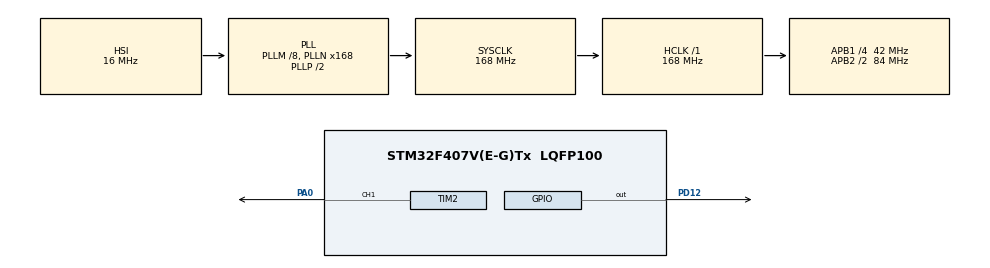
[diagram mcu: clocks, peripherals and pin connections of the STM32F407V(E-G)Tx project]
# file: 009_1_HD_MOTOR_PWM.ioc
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Mcu.Family=STM32F4
Mcu.Name=STM32F407V(E-G)Tx
Mcu.Package=LQFP100
NVIC.PriorityGroup=NVIC_PRIORITYGROUP_4
PA0-WKUP.Signal=S_TIM2_CH1_ETR
PD12.Signal=GPIO_Output
ProjectManager.HeapSize=0x200
ProjectManager.StackSize=0x400
ProjectManager.TargetToolchain=STM32CubeIDE
RCC.48MHZClocksFreq_Value=84000000
RCC.AHBFreq_Value=168000000
RCC.APB1CLKDivider=RCC_HCLK_DIV4
RCC.APB1Freq_Value=42000000
RCC.APB1TimFreq_Value=84000000
RCC.APB2CLKDivider=RCC_HCLK_DIV2
RCC.APB2Freq_Value=84000000
RCC.APB2TimFreq_Value=168000000
RCC.CortexFreq_Value=168000000
RCC.HCLKFreq_Value=168000000
RCC.HSE_VALUE=25000000
RCC.HSI_VALUE=16000000
RCC.LSE_VALUE=32768
RCC.PLLM=8
RCC.PLLN=168
RCC.SYSCLKFreq_VALUE=168000000
RCC.SYSCLKSource=RCC_SYSCLKSOURCE_PLLCLK
RCC.VCOOutputFreq_Value=336000000
SH.S_TIM2_CH1_ETR.0=TIM2_CH1,PWM Generation1 CH1
TIM2.Channel-PWM\ Generation1\ CH1=TIM_CHANNEL_1
TIM2.Period=124
TIM2.Prescaler=83
board=custom

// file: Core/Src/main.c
/* USER CODE BEGIN Header */
/**
  ******************************************************************************
  * @file           : main.c
  * @brief          : Main program body
  ******************************************************************************
  * @attention
  *
  * <h2><center>&copy; Copyright (c) 2020 STMicroelectronics.
  * All rights reserved.</center></h2>
  *
  * This software component is licensed by ST under BSD 3-Clause license,
  * the "License"; You may not use this file except in compliance with the
  * License. You may obtain a copy of the License at:
  *                        opensource.org/licenses/BSD-3-Clause
  *
  ******************************************************************************
  */
/* USER CODE END Header */

#include "main.h"

/* USER CODE BEGIN Includes */

int count;
int i;

/* USER CODE END Includes */

TIM_HandleTypeDef htim2;

void SystemClock_Config(void);
static void MX_GPIO_Init(void);
static void MX_TIM2_Init(void);

int main(void)
{

  /* MCU Configuration--------------------------------------------------------*/

  /* Reset of all peripherals, Initializes the Flash interface and the Systick. */
  HAL_Init();

  /* Configure the system clock */
  SystemClock_Config();

  /* Initialize all configured peripherals */
  MX_GPIO_Init();
  MX_TIM2_Init();
  /* USER CODE BEGIN 2 */
 HAL_TIM_PWM_Start(&htim2, TIM_CHANNEL_1);
  /* USER CODE END 2 */

  /* Infinite loop */
  /* USER CODE BEGIN WHILE */
  while (1)
  {
	  for(i = 0; i <= 125; i++)
	  {
		  __HAL_TIM_SET_COMPARE(&htim2, TIM_CHANNEL_1, i);
		  HAL_Delay(50);
		  count = i;

	  }
	  HAL_GPIO_WritePin(GPIOD, GPIO_PIN_12, GPIO_PIN_SET);
    /* USER CODE END WHILE */

  }
}

void SystemClock_Config(void)
{
  RCC_OscInitTypeDef RCC_OscInitStruct = {0};
  RCC_ClkInitTypeDef RCC_ClkInitStruct = {0};

  /** Configure the main internal regulator output voltage
  */
  __HAL_RCC_PWR_CLK_ENABLE();
  __HAL_PWR_VOLTAGESCALING_CONFIG(PWR_REGULATOR_VOLTAGE_SCALE1);
  /** Initializes the CPU, AHB and APB busses clocks
  */
  RCC_OscInitStruct.OscillatorType = RCC_OSCILLATORTYPE_HSI;
  RCC_OscInitStruct.HSIState = RCC_HSI_ON;
  RCC_OscInitStruct.HSICalibrationValue = RCC_HSICALIBRATION_DEFAULT;
  RCC_OscInitStruct.PLL.PLLState = RCC_PLL_ON;
  RCC_OscInitStruct.PLL.PLLSource = RCC_PLLSOURCE_HSI;
  RCC_OscInitStruct.PLL.PLLM = 8;
  RCC_OscInitStruct.PLL.PLLN = 168;
  RCC_OscInitStruct.PLL.PLLP = RCC_PLLP_DIV2;
  RCC_OscInitStruct.PLL.PLLQ = 4;
  if (HAL_RCC_OscConfig(&RCC_OscInitStruct) != HAL_OK)
  {
    Error_Handler();
  }
  /** Initializes the CPU, AHB and APB busses clocks
  */
  RCC_ClkInitStruct.ClockType = RCC_CLOCKTYPE_HCLK|RCC_CLOCKTYPE_SYSCLK
                              |RCC_CLOCKTYPE_PCLK1|RCC_CLOCKTYPE_PCLK2;
  RCC_ClkInitStruct.SYSCLKSource = RCC_SYSCLKSOURCE_PLLCLK;
  RCC_ClkInitStruct.AHBCLKDivider = RCC_SYSCLK_DIV1;
  RCC_ClkInitStruct.APB1CLKDivider = RCC_HCLK_DIV4;
  RCC_ClkInitStruct.APB2CLKDivider = RCC_HCLK_DIV2;

  if (HAL_RCC_ClockConfig(&RCC_ClkInitStruct, FLASH_LATENCY_5) != HAL_OK)
  {
    Error_Handler();
  }
}

static void MX_TIM2_Init(void)
{

  TIM_MasterConfigTypeDef sMasterConfig = {0};
  TIM_OC_InitTypeDef sConfigOC = {0};

  htim2.Instance = TIM2;
  htim2.Init.Prescaler = 83;
  htim2.Init.CounterMode = TIM_COUNTERMODE_UP;
  htim2.Init.Period = 124;
  htim2.Init.ClockDivision = TIM_CLOCKDIVISION_DIV1;
  htim2.Init.AutoReloadPreload = TIM_AUTORELOAD_PRELOAD_DISABLE;
  if (HAL_TIM_PWM_Init(&htim2) != HAL_OK)
  {
    Error_Handler();
  }
  sMasterConfig.MasterOutputTrigger = TIM_TRGO_RESET;
  sMasterConfig.MasterSlaveMode = TIM_MASTERSLAVEMODE_DISABLE;
  if (HAL_TIMEx_MasterConfigSynchronization(&htim2, &sMasterConfig) != HAL_OK)
  {
    Error_Handler();
  }
  sConfigOC.OCMode = TIM_OCMODE_PWM1;
  sConfigOC.Pulse = 0;
  sConfigOC.OCPolarity = TIM_OCPOLARITY_HIGH;
  sConfigOC.OCFastMode = TIM_OCFAST_DISABLE;
  if (HAL_TIM_PWM_ConfigChannel(&htim2, &sConfigOC, TIM_CHANNEL_1) != HAL_OK)
  {
    Error_Handler();
  }
  HAL_TIM_MspPostInit(&htim2);

}

static void MX_GPIO_Init(void)
{
  GPIO_InitTypeDef GPIO_InitStruct = {0};

  /* GPIO Ports Clock Enable */
  __HAL_RCC_GPIOA_CLK_ENABLE();
  __HAL_RCC_GPIOD_CLK_ENABLE();

  /*Configure GPIO pin Output Level */
  HAL_GPIO_WritePin(GPIOD, GPIO_PIN_12, GPIO_PIN_RESET);

  /*Configure GPIO pin : PD12 */
  GPIO_InitStruct.Pin = GPIO_PIN_12;
  GPIO_InitStruct.Mode = GPIO_MODE_OUTPUT_PP;
  GPIO_InitStruct.Pull = GPIO_NOPULL;
  GPIO_InitStruct.Speed = GPIO_SPEED_FREQ_LOW;
  HAL_GPIO_Init(GPIOD, &GPIO_InitStruct);

}

void Error_Handler(void)
{
}

/************************ (C) COPYRIGHT STMicroelectronics *****END OF FILE****/
